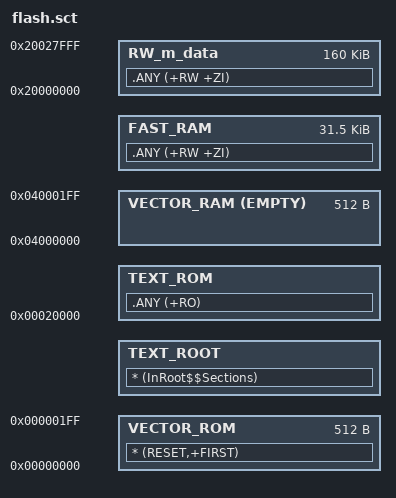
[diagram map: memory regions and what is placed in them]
#! armcc -E


; must use "VECTOR_RAM", "RW_m_data", "VECTOR_ROM" as names to work with "InstallIRQHandler()" API

LR_IROM1 0 16*1024 { ; load region size_region
  
  ; >>> RO regions
	  VECTOR_ROM +0 0x200 { ; vector table
		* (RESET,+FIRST)
	  }
	  
	  TEXT_ROOT +0  { ; load address = execution address
		* (InRoot$$Sections)
	  }
  ; <<<
}

LR_IROM2 0x00020000 384*1024 {

	  TEXT_ROM +0  { ; load address = execution address
		.ANY (+RO)
	  }

  ; >>> RAMX regions
	  ; RAM vector table, unless "InstallIRQHandler()" is called, not used
	  VECTOR_RAM 0x04000000 EMPTY 0x200 { ; RAM vector region (in RAMX)
	  } 

	  FAST_RAM +0 32*1024-0x200 {
		 .ANY (+RW +ZI)
	  }

  ; <<<
  
  ; >>> AHB RAM (2 cycles access) regions, main R/W
	  RW_m_data 0x20000000 (64+64+32)*1024 { ; RW data
		.ANY (+RW +ZI)
	  }
  ; <<<
  
  ; >>> SDRAM >>>
	  ;RW_FB 0xA0000000 EMPTY UNINIT 1024*1024  {
	  ;}
	  
	  ;RW_SDRAM 0xA0100000 EMPTY UNINIT (32-1)*1024*1024  {
	  ;}
; <<<
}
